# ECC_AGGR0_ECC_AGGR register map
Vendor: Texas Instruments
Peripheral module from a debugger description file (folder am65x).
Registers are 32-bit, access not given, reset 0x0 unless marked. A register's access mark holds for its fields unless they carry their own. Offsets are as the file gives them; lines under a group give offsets from that group; [hi:lo] are bit positions; {n}, {i} and the like mark numbered series; 'fields as' and 'values as' point back to an identical list; <NAME> marks a mode.

## ECC_AGGR0_ECC_AGGR (part 1 of 2)
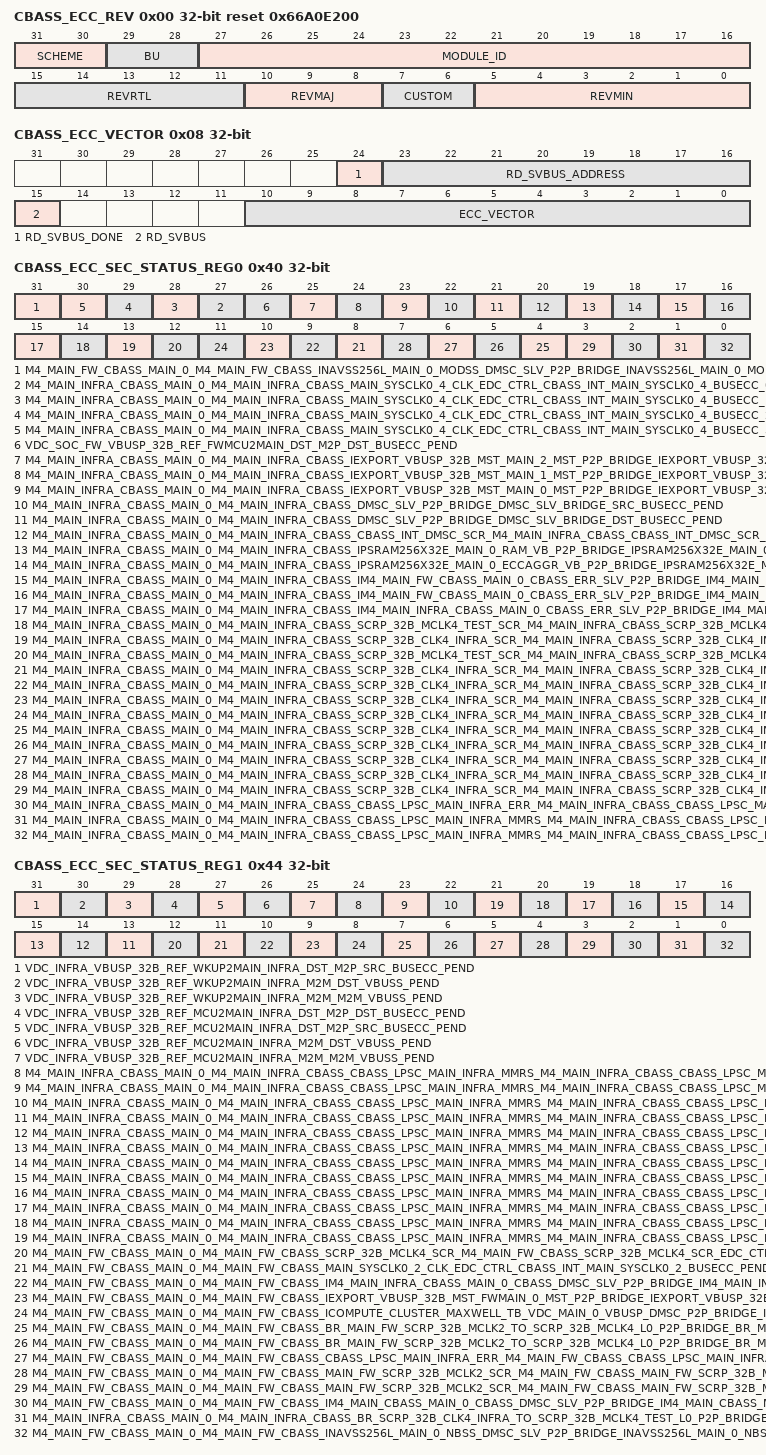
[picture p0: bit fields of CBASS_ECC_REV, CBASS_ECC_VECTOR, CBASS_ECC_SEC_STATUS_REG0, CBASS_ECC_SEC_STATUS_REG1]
0x00 CBASS_ECC_REV ro reset 0x66A0E200 — Return to the . Revision parameters
  [31:30] SCHEME
  [29:28] BU
  [27:16] MODULE_ID
  [15:11] REVRTL — RTL version
  [10:8] REVMAJ — Major version
  [7:6] CUSTOM — Custom version
  [5:0] REVMIN — Minor version
0x08 CBASS_ECC_VECTOR — Return to the . ECC Vector Register
  [24] RD_SVBUS_DONE — Status to indicate if read on serial VBUS is complete, write of any value will clear this bit. (access RW1C)
  [23:16] RD_SVBUS_ADDRESS rw — Read address
  [15] RD_SVBUS — Write 1 to trigger a read on the serial VBUS (access RW1S)
  [10:0] ECC_VECTOR rw — Value written to select the corresponding ECC RAM for control or status
0x0C CBASS_ECC_STAT ro reset 0x44 — Return to the . Misc Status
  [10:0] NUM_RAMS — Indicates the number of RAMS serviced by the ECC aggregator
0x3C CBASS_ECC_SEC_EOI_REG — Return to the . EOI Register
  [0] EOI_WR — EOI Register (access RW1S)
0x40 CBASS_ECC_SEC_STATUS_REG0 — Return to the . Interrupt Status Register 0
  [31] M4_MAIN_FW_CBASS_MAIN_0_M4_MAIN_FW_CBASS_INAVSS256L_MAIN_0_MODSS_DMSC_SLV_P2P_BRIDGE_INAVSS256L_MAIN_0_MODSS_DMSC_SLV_BRIDGE_BUSECC_PEND — Interrupt Pending Status for m4_main_fw_cbass_main_0_m4_main_fw_cbass_Inavss256l_main_0_modss_dmsc_slv_p2p_bridge_Inavss256l_main_0_modss_dmsc_slv_bridge_busecc__pend (access RW1S)
  [n+27] M4_MAIN_INFRA_CBASS_MAIN_0_M4_MAIN_INFRA_CBASS_MAIN_SYSCLK0_4_CLK_EDC_CTRL_CBASS_INT_MAIN_SYSCLK0_4_BUSECC_{n}_PEND (n=0..3) — Interrupt Pending Status for m4_main_infra_cbass_main_0_m4_main_infra_cbass_main_sysclk0_4_clk_edc_ctrl_cbass_int_main_sysclk0_4_busecc_{n}__pend (access RW1S)
  [26] VDC_SOC_FW_VBUSP_32B_REF_FWMCU2MAIN_DST_M2P_DST_BUSECC_PEND — Interrupt Pending Status for vdc_soc_fw_vbusp_32b_ref_fwmcu2main_dst_m2p_dst_busecc__pend (access RW1S)
  [25] M4_MAIN_INFRA_CBASS_MAIN_0_M4_MAIN_INFRA_CBASS_IEXPORT_VBUSP_32B_MST_MAIN_2_MST_P2P_BRIDGE_IEXPORT_VBUSP_32B_MST_MAIN_2_MST_BRIDGE_BUSECC_PEND — Interrupt Pending Status for m4_main_infra_cbass_main_0_m4_main_infra_cbass_Iexport_vbusp_32b_mst_main_2_mst_p2p_bridge_Iexport_vbusp_32b_mst_main_2_mst_bridge_busecc__pend (access RW1S)
  [24] M4_MAIN_INFRA_CBASS_MAIN_0_M4_MAIN_INFRA_CBASS_IEXPORT_VBUSP_32B_MST_MAIN_1_MST_P2P_BRIDGE_IEXPORT_VBUSP_32B_MST_MAIN_1_MST_BRIDGE_BUSECC_PEND — Interrupt Pending Status for m4_main_infra_cbass_main_0_m4_main_infra_cbass_Iexport_vbusp_32b_mst_main_1_mst_p2p_bridge_Iexport_vbusp_32b_mst_main_1_mst_bridge_busecc__pend (access RW1S)
  [23] M4_MAIN_INFRA_CBASS_MAIN_0_M4_MAIN_INFRA_CBASS_IEXPORT_VBUSP_32B_MST_MAIN_0_MST_P2P_BRIDGE_IEXPORT_VBUSP_32B_MST_MAIN_0_MST_BRIDGE_BUSECC_PEND — Interrupt Pending Status for m4_main_infra_cbass_main_0_m4_main_infra_cbass_Iexport_vbusp_32b_mst_main_0_mst_p2p_bridge_Iexport_vbusp_32b_mst_main_0_mst_bridge_busecc__pend (access RW1S)
  [22] M4_MAIN_INFRA_CBASS_MAIN_0_M4_MAIN_INFRA_CBASS_DMSC_SLV_P2P_BRIDGE_DMSC_SLV_BRIDGE_SRC_BUSECC_PEND — Interrupt Pending Status for m4_main_infra_cbass_main_0_m4_main_infra_cbass_dmsc_slv_p2p_bridge_dmsc_slv_bridge_src_busecc__pend (access RW1S)
  [21] M4_MAIN_INFRA_CBASS_MAIN_0_M4_MAIN_INFRA_CBASS_DMSC_SLV_P2P_BRIDGE_DMSC_SLV_BRIDGE_DST_BUSECC_PEND — Interrupt Pending Status for m4_main_infra_cbass_main_0_m4_main_infra_cbass_dmsc_slv_p2p_bridge_dmsc_slv_bridge_dst_busecc__pend (access RW1S)
  [20] M4_MAIN_INFRA_CBASS_MAIN_0_M4_MAIN_INFRA_CBASS_CBASS_INT_DMSC_SCR_M4_MAIN_INFRA_CBASS_CBASS_INT_DMSC_SCR_EDC_CTRL_BUSECC_PEND — Interrupt Pending Status for m4_main_infra_cbass_main_0_m4_main_infra_cbass_cbass_int_dmsc_scr_m4_main_infra_cbass_cbass_int_dmsc_scr_edc_ctrl_busecc__pend (access RW1S)
  [19] M4_MAIN_INFRA_CBASS_MAIN_0_M4_MAIN_INFRA_CBASS_IPSRAM256X32E_MAIN_0_RAM_VB_P2P_BRIDGE_IPSRAM256X32E_MAIN_0_RAM_VB_BRIDGE_BUSECC_PEND — Interrupt Pending Status for m4_main_infra_cbass_main_0_m4_main_infra_cbass_Ipsram256x32e_main_0_ram_vb_p2p_bridge_Ipsram256x32e_main_0_ram_vb_bridge_busecc__pend (access RW1S)
  [18] M4_MAIN_INFRA_CBASS_MAIN_0_M4_MAIN_INFRA_CBASS_IPSRAM256X32E_MAIN_0_ECCAGGR_VB_P2P_BRIDGE_IPSRAM256X32E_MAIN_0_ECCAGGR_VB_BRIDGE_BUSECC_PEND — Interrupt Pending Status for m4_main_infra_cbass_main_0_m4_main_infra_cbass_Ipsram256x32e_main_0_eccaggr_vb_p2p_bridge_Ipsram256x32e_main_0_eccaggr_vb_bridge_busecc__pend (access RW1S)
  [17] M4_MAIN_INFRA_CBASS_MAIN_0_M4_MAIN_INFRA_CBASS_IM4_MAIN_FW_CBASS_MAIN_0_CBASS_ERR_SLV_P2P_BRIDGE_IM4_MAIN_FW_CBASS_MAIN_0_CBASS_ERR_SLV_BRIDGE_SRC_BUSECC_PEND — Interrupt Pending Status for m4_main_infra_cbass_main_0_m4_main_infra_cbass_Im4_main_fw_cbass_main_0_cbass_err_slv_p2p_bridge_Im4_main_fw_cbass_main_0_cbass_err_slv_bridge_src_busecc__pend (access RW1S)
  [16] M4_MAIN_INFRA_CBASS_MAIN_0_M4_MAIN_INFRA_CBASS_IM4_MAIN_FW_CBASS_MAIN_0_CBASS_ERR_SLV_P2P_BRIDGE_IM4_MAIN_FW_CBASS_MAIN_0_CBASS_ERR_SLV_BRIDGE_DST_BUSECC_PEND — Interrupt Pending Status for m4_main_infra_cbass_main_0_m4_main_infra_cbass_Im4_main_fw_cbass_main_0_cbass_err_slv_p2p_bridge_Im4_main_fw_cbass_main_0_cbass_err_slv_bridge_dst_busecc__pend (access RW1S)
  [15] M4_MAIN_INFRA_CBASS_MAIN_0_M4_MAIN_INFRA_CBASS_IM4_MAIN_INFRA_CBASS_MAIN_0_CBASS_ERR_SLV_P2P_BRIDGE_IM4_MAIN_INFRA_CBASS_MAIN_0_CBASS_ERR_SLV_BRIDGE_BUSECC_PEND — Interrupt Pending Status for m4_main_infra_cbass_main_0_m4_main_infra_cbass_Im4_main_infra_cbass_main_0_cbass_err_slv_p2p_bridge_Im4_main_infra_cbass_main_0_cbass_err_slv_bridge_busecc__pend (access RW1S)
  [14] M4_MAIN_INFRA_CBASS_MAIN_0_M4_MAIN_INFRA_CBASS_SCRP_32B_MCLK4_TEST_SCR_M4_MAIN_INFRA_CBASS_SCRP_32B_MCLK4_TEST_SCR_EDC_CTRL_BUSECC_1_PEND — Interrupt Pending Status for m4_main_infra_cbass_main_0_m4_main_infra_cbass_SCRP_32b_MCLK4_test_scr_m4_main_infra_cbass_SCRP_32b_MCLK4_test_scr_edc_ctrl_busecc_1__pend (access RW1S)
  [13] M4_MAIN_INFRA_CBASS_MAIN_0_M4_MAIN_INFRA_CBASS_SCRP_32B_CLK4_INFRA_SCR_M4_MAIN_INFRA_CBASS_SCRP_32B_CLK4_INFRA_SCR_EDC_CTRL_BUSECC_9_PEND — Interrupt Pending Status for m4_main_infra_cbass_main_0_m4_main_infra_cbass_SCRP_32b_CLK4_infra_scr_m4_main_infra_cbass_SCRP_32b_CLK4_infra_scr_edc_ctrl_busecc_9__pend (access RW1S)
  [12] M4_MAIN_INFRA_CBASS_MAIN_0_M4_MAIN_INFRA_CBASS_SCRP_32B_MCLK4_TEST_SCR_M4_MAIN_INFRA_CBASS_SCRP_32B_MCLK4_TEST_SCR_EDC_CTRL_BUSECC_0_PEND — Interrupt Pending Status for m4_main_infra_cbass_main_0_m4_main_infra_cbass_SCRP_32b_MCLK4_test_scr_m4_main_infra_cbass_SCRP_32b_MCLK4_test_scr_edc_ctrl_busecc_0__pend (access RW1S)
  [n+3] M4_MAIN_INFRA_CBASS_MAIN_0_M4_MAIN_INFRA_CBASS_SCRP_32B_CLK4_INFRA_SCR_M4_MAIN_INFRA_CBASS_SCRP_32B_CLK4_INFRA_SCR_EDC_CTRL_BUSECC_{n}_PEND (n=5..8) — Interrupt Pending Status for m4_main_infra_cbass_main_0_m4_main_infra_cbass_SCRP_32b_CLK4_infra_scr_m4_main_infra_cbass_SCRP_32b_CLK4_infra_scr_edc_ctrl_busecc_{n}__pend (access RW1S)
  [n+4] M4_MAIN_INFRA_CBASS_MAIN_0_M4_MAIN_INFRA_CBASS_SCRP_32B_CLK4_INFRA_SCR_M4_MAIN_INFRA_CBASS_SCRP_32B_CLK4_INFRA_SCR_EDC_CTRL_BUSECC_{n}_PEND (n=0..3) — Interrupt Pending Status for m4_main_infra_cbass_main_0_m4_main_infra_cbass_SCRP_32b_CLK4_infra_scr_m4_main_infra_cbass_SCRP_32b_CLK4_infra_scr_edc_ctrl_busecc_{n}__pend (access RW1S)
  [3] M4_MAIN_INFRA_CBASS_MAIN_0_M4_MAIN_INFRA_CBASS_SCRP_32B_CLK4_INFRA_SCR_M4_MAIN_INFRA_CBASS_SCRP_32B_CLK4_INFRA_SCR_EDC_CTRL_BUSECC_4_PEND — Interrupt Pending Status for m4_main_infra_cbass_main_0_m4_main_infra_cbass_SCRP_32b_CLK4_infra_scr_m4_main_infra_cbass_SCRP_32b_CLK4_infra_scr_edc_ctrl_busecc_4__pend (access RW1S)
  [2] M4_MAIN_INFRA_CBASS_MAIN_0_M4_MAIN_INFRA_CBASS_CBASS_LPSC_MAIN_INFRA_ERR_M4_MAIN_INFRA_CBASS_CBASS_LPSC_MAIN_INFRA_ERR_EDC_CTRL_BUSECC_PEND — Interrupt Pending Status for m4_main_infra_cbass_main_0_m4_main_infra_cbass_cbass_LPSC_main_infra_err_m4_main_infra_cbass_cbass_LPSC_main_infra_err_edc_ctrl_busecc__pend (access RW1S)
  [1] M4_MAIN_INFRA_CBASS_MAIN_0_M4_MAIN_INFRA_CBASS_CBASS_LPSC_MAIN_INFRA_MMRS_M4_MAIN_INFRA_CBASS_CBASS_LPSC_MAIN_INFRA_MMRS_EDC_CTRL_BUSECC_10_PEND — Interrupt Pending Status for m4_main_infra_cbass_main_0_m4_main_infra_cbass_cbass_LPSC_main_infra_mmrs_m4_main_infra_cbass_cbass_LPSC_main_infra_mmrs_edc_ctrl_busecc_10__pend (access RW1S)
  [0] M4_MAIN_INFRA_CBASS_MAIN_0_M4_MAIN_INFRA_CBASS_CBASS_LPSC_MAIN_INFRA_MMRS_M4_MAIN_INFRA_CBASS_CBASS_LPSC_MAIN_INFRA_MMRS_EDC_CTRL_BUSECC_0_PEND — Interrupt Pending Status for m4_main_infra_cbass_main_0_m4_main_infra_cbass_cbass_LPSC_main_infra_mmrs_m4_main_infra_cbass_cbass_LPSC_main_infra_mmrs_edc_ctrl_busecc_0__pend (access RW1S)
0x44 CBASS_ECC_SEC_STATUS_REG1 — Return to the . Interrupt Status Register 1
  [31] VDC_INFRA_VBUSP_32B_REF_WKUP2MAIN_INFRA_DST_M2P_SRC_BUSECC_PEND — Interrupt Pending Status for vdc_infra_vbusp_32b_ref_wkup2main_infra_dst_m2p_src_busecc__pend (access RW1S)
  [30] VDC_INFRA_VBUSP_32B_REF_WKUP2MAIN_INFRA_M2M_DST_VBUSS_PEND — Interrupt Pending Status for vdc_infra_vbusp_32b_ref_wkup2main_infra_m2m_dst_vbuss__pend (access RW1S)
  [29] VDC_INFRA_VBUSP_32B_REF_WKUP2MAIN_INFRA_M2M_M2M_VBUSS_PEND — Interrupt Pending Status for vdc_infra_vbusp_32b_ref_wkup2main_infra_m2m_m2m_vbuss__pend (access RW1S)
  [28] VDC_INFRA_VBUSP_32B_REF_MCU2MAIN_INFRA_DST_M2P_DST_BUSECC_PEND — Interrupt Pending Status for vdc_infra_vbusp_32b_ref_mcu2main_infra_dst_m2p_dst_busecc__pend (access RW1S)
  [27] VDC_INFRA_VBUSP_32B_REF_MCU2MAIN_INFRA_DST_M2P_SRC_BUSECC_PEND — Interrupt Pending Status for vdc_infra_vbusp_32b_ref_mcu2main_infra_dst_m2p_src_busecc__pend (access RW1S)
  [26] VDC_INFRA_VBUSP_32B_REF_MCU2MAIN_INFRA_M2M_DST_VBUSS_PEND — Interrupt Pending Status for vdc_infra_vbusp_32b_ref_mcu2main_infra_m2m_dst_vbuss__pend (access RW1S)
  [25] VDC_INFRA_VBUSP_32B_REF_MCU2MAIN_INFRA_M2M_M2M_VBUSS_PEND — Interrupt Pending Status for vdc_infra_vbusp_32b_ref_mcu2main_infra_m2m_m2m_vbuss__pend (access RW1S)
  [24] M4_MAIN_INFRA_CBASS_MAIN_0_M4_MAIN_INFRA_CBASS_CBASS_LPSC_MAIN_INFRA_MMRS_M4_MAIN_INFRA_CBASS_CBASS_LPSC_MAIN_INFRA_MMRS_EDC_CTRL_BUSECC_13_PEND — Interrupt Pending Status for m4_main_infra_cbass_main_0_m4_main_infra_cbass_cbass_LPSC_main_infra_mmrs_m4_main_infra_cbass_cbass_LPSC_main_infra_mmrs_edc_ctrl_busecc_13__pend (access RW1S)
  [23] M4_MAIN_INFRA_CBASS_MAIN_0_M4_MAIN_INFRA_CBASS_CBASS_LPSC_MAIN_INFRA_MMRS_M4_MAIN_INFRA_CBASS_CBASS_LPSC_MAIN_INFRA_MMRS_EDC_CTRL_BUSECC_12_PEND — Interrupt Pending Status for m4_main_infra_cbass_main_0_m4_main_infra_cbass_cbass_LPSC_main_infra_mmrs_m4_main_infra_cbass_cbass_LPSC_main_infra_mmrs_edc_ctrl_busecc_12__pend (access RW1S)
  [22] M4_MAIN_INFRA_CBASS_MAIN_0_M4_MAIN_INFRA_CBASS_CBASS_LPSC_MAIN_INFRA_MMRS_M4_MAIN_INFRA_CBASS_CBASS_LPSC_MAIN_INFRA_MMRS_EDC_CTRL_BUSECC_11_PEND — Interrupt Pending Status for m4_main_infra_cbass_main_0_m4_main_infra_cbass_cbass_LPSC_main_infra_mmrs_m4_main_infra_cbass_cbass_LPSC_main_infra_mmrs_edc_ctrl_busecc_11__pend (access RW1S)
  [n+12] M4_MAIN_INFRA_CBASS_MAIN_0_M4_MAIN_INFRA_CBASS_CBASS_LPSC_MAIN_INFRA_MMRS_M4_MAIN_INFRA_CBASS_CBASS_LPSC_MAIN_INFRA_MMRS_EDC_CTRL_BUSECC_{n}_PEND (n=1..9) — Interrupt Pending Status for m4_main_infra_cbass_main_0_m4_main_infra_cbass_cbass_LPSC_main_infra_mmrs_m4_main_infra_cbass_cbass_LPSC_main_infra_mmrs_edc_ctrl_busecc_{n}__pend (access RW1S)
  [12] M4_MAIN_FW_CBASS_MAIN_0_M4_MAIN_FW_CBASS_SCRP_32B_MCLK4_SCR_M4_MAIN_FW_CBASS_SCRP_32B_MCLK4_SCR_EDC_CTRL_BUSECC_PEND — Interrupt Pending Status for m4_main_fw_cbass_main_0_m4_main_fw_cbass_SCRP_32b_MCLK4_scr_m4_main_fw_cbass_SCRP_32b_MCLK4_scr_edc_ctrl_busecc__pend (access RW1S)
  [11] M4_MAIN_FW_CBASS_MAIN_0_M4_MAIN_FW_CBASS_MAIN_SYSCLK0_2_CLK_EDC_CTRL_CBASS_INT_MAIN_SYSCLK0_2_BUSECC_PEND — Interrupt Pending Status for m4_main_fw_cbass_main_0_m4_main_fw_cbass_main_sysclk0_2_clk_edc_ctrl_cbass_int_main_sysclk0_2_busecc__pend (access RW1S)
  [10] M4_MAIN_FW_CBASS_MAIN_0_M4_MAIN_FW_CBASS_IM4_MAIN_INFRA_CBASS_MAIN_0_CBASS_DMSC_SLV_P2P_BRIDGE_IM4_MAIN_INFRA_CBASS_MAIN_0_CBASS_DMSC_SLV_BRIDGE_BUSECC_PEND — Interrupt Pending Status for m4_main_fw_cbass_main_0_m4_main_fw_cbass_Im4_main_infra_cbass_main_0_cbass_dmsc_slv_p2p_bridge_Im4_main_infra_cbass_main_0_cbass_dmsc_slv_bridge_busecc__pend (access RW1S)
  [9] M4_MAIN_FW_CBASS_MAIN_0_M4_MAIN_FW_CBASS_IEXPORT_VBUSP_32B_MST_FWMAIN_0_MST_P2P_BRIDGE_IEXPORT_VBUSP_32B_MST_FWMAIN_0_MST_BRIDGE_BUSECC_PEND — Interrupt Pending Status for m4_main_fw_cbass_main_0_m4_main_fw_cbass_Iexport_vbusp_32b_mst_fwmain_0_mst_p2p_bridge_Iexport_vbusp_32b_mst_fwmain_0_mst_bridge_busecc__pend (access RW1S)
  [8] M4_MAIN_FW_CBASS_MAIN_0_M4_MAIN_FW_CBASS_ICOMPUTE_CLUSTER_MAXWELL_TB_VDC_MAIN_0_VBUSP_DMSC_P2P_BRIDGE_ICOMPUTE_CLUSTER_MAXWELL_TB_VDC_MAIN_0_VBUSP_DMSC_BRIDGE_BUSECC_PEND — Interrupt Pending Status for m4_main_fw_cbass_main_0_m4_main_fw_cbass_Icompute_cluster_maxwell_tb_vdc_main_0_vbusp_dmsc_p2p_bridge_Icompute_cluster_maxwell_tb_vdc_main_0_vbusp_dmsc_bridge_busecc__pend (access RW1S)
  [7] M4_MAIN_FW_CBASS_MAIN_0_M4_MAIN_FW_CBASS_BR_MAIN_FW_SCRP_32B_MCLK2_TO_SCRP_32B_MCLK4_L0_P2P_BRIDGE_BR_MAIN_FW_SCRP_32B_MCLK2_TO_SCRP_32B_MCLK4_L0_BRIDGE_SRC_BUSECC_PEND — Interrupt Pending Status for m4_main_fw_cbass_main_0_m4_main_fw_cbass_br_main_FW_SCRP_32b_MCLK2_to_SCRP_32b_MCLK4_l0_p2p_bridge_br_main_FW_SCRP_32b_MCLK2_to_SCRP_32b_MCLK4_l0_bridge_src_busecc__pend (access RW1S)
  [6] M4_MAIN_FW_CBASS_MAIN_0_M4_MAIN_FW_CBASS_BR_MAIN_FW_SCRP_32B_MCLK2_TO_SCRP_32B_MCLK4_L0_P2P_BRIDGE_BR_MAIN_FW_SCRP_32B_MCLK2_TO_SCRP_32B_MCLK4_L0_BRIDGE_DST_BUSECC_PEND — Interrupt Pending Status for m4_main_fw_cbass_main_0_m4_main_fw_cbass_br_main_FW_SCRP_32b_MCLK2_to_SCRP_32b_MCLK4_l0_p2p_bridge_br_main_FW_SCRP_32b_MCLK2_to_SCRP_32b_MCLK4_l0_bridge_dst_busecc__pend (access RW1S)
  [5] M4_MAIN_FW_CBASS_MAIN_0_M4_MAIN_FW_CBASS_CBASS_LPSC_MAIN_INFRA_ERR_M4_MAIN_FW_CBASS_CBASS_LPSC_MAIN_INFRA_ERR_EDC_CTRL_BUSECC_PEND — Interrupt Pending Status for m4_main_fw_cbass_main_0_m4_main_fw_cbass_cbass_LPSC_main_infra_err_m4_main_fw_cbass_cbass_LPSC_main_infra_err_edc_ctrl_busecc__pend (access RW1S)
  [4] M4_MAIN_FW_CBASS_MAIN_0_M4_MAIN_FW_CBASS_MAIN_FW_SCRP_32B_MCLK2_SCR_M4_MAIN_FW_CBASS_MAIN_FW_SCRP_32B_MCLK2_SCR_EDC_CTRL_BUSECC_1_PEND — Interrupt Pending Status for m4_main_fw_cbass_main_0_m4_main_fw_cbass_main_FW_SCRP_32b_MCLK2_scr_m4_main_fw_cbass_main_FW_SCRP_32b_MCLK2_scr_edc_ctrl_busecc_1__pend (access RW1S)
  [3] M4_MAIN_FW_CBASS_MAIN_0_M4_MAIN_FW_CBASS_MAIN_FW_SCRP_32B_MCLK2_SCR_M4_MAIN_FW_CBASS_MAIN_FW_SCRP_32B_MCLK2_SCR_EDC_CTRL_BUSECC_0_PEND — Interrupt Pending Status for m4_main_fw_cbass_main_0_m4_main_fw_cbass_main_FW_SCRP_32b_MCLK2_scr_m4_main_fw_cbass_main_FW_SCRP_32b_MCLK2_scr_edc_ctrl_busecc_0__pend (access RW1S)
  [2] M4_MAIN_FW_CBASS_MAIN_0_M4_MAIN_FW_CBASS_IM4_MAIN_CBASS_MAIN_0_CBASS_DMSC_SLV_P2P_BRIDGE_IM4_MAIN_CBASS_MAIN_0_CBASS_DMSC_SLV_BRIDGE_BUSECC_PEND — Interrupt Pending Status for m4_main_fw_cbass_main_0_m4_main_fw_cbass_Im4_main_cbass_main_0_cbass_dmsc_slv_p2p_bridge_Im4_main_cbass_main_0_cbass_dmsc_slv_bridge_busecc__pend (access RW1S)
  [1] M4_MAIN_INFRA_CBASS_MAIN_0_M4_MAIN_INFRA_CBASS_BR_SCRP_32B_CLK4_INFRA_TO_SCRP_32B_MCLK4_TEST_L0_P2P_BRIDGE_BR_SCRP_32B_CLK4_INFRA_TO_SCRP_32B_MCLK4_TEST_L0_BRIDGE_BUSECC_PEND — Interrupt Pending Status for m4_main_infra_cbass_main_0_m4_main_infra_cbass_br_SCRP_32b_CLK4_infra_to_SCRP_32b_MCLK4_test_l0_p2p_bridge_br_SCRP_32b_CLK4_infra_to_SCRP_32b_MCLK4_test_l0_bridge_busecc__pend (access RW1S)
  [0] M4_MAIN_FW_CBASS_MAIN_0_M4_MAIN_FW_CBASS_INAVSS256L_MAIN_0_NBSS_DMSC_SLV_P2P_BRIDGE_INAVSS256L_MAIN_0_NBSS_DMSC_SLV_BRIDGE_BUSECC_PEND — Interrupt Pending Status for m4_main_fw_cbass_main_0_m4_main_fw_cbass_Inavss256l_main_0_nbss_dmsc_slv_p2p_bridge_Inavss256l_main_0_nbss_dmsc_slv_bridge_busecc__pend (access RW1S)
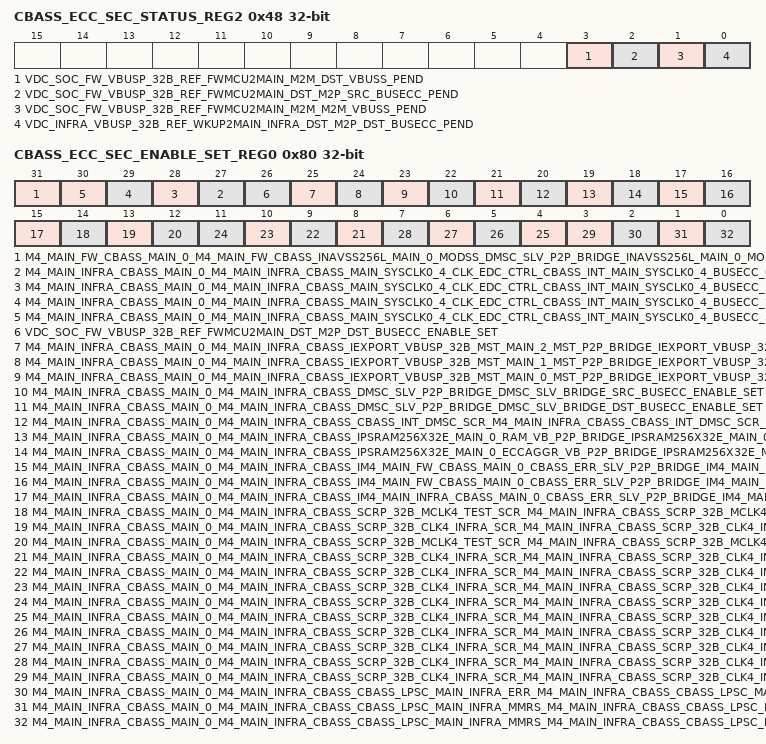
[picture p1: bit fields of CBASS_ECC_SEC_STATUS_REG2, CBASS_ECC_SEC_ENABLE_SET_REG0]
0x48 CBASS_ECC_SEC_STATUS_REG2 — Return to the . Interrupt Status Register 2
  [3] VDC_SOC_FW_VBUSP_32B_REF_FWMCU2MAIN_M2M_DST_VBUSS_PEND — Interrupt Pending Status for vdc_soc_fw_vbusp_32b_ref_fwmcu2main_m2m_dst_vbuss__pend (access RW1S)
  [2] VDC_SOC_FW_VBUSP_32B_REF_FWMCU2MAIN_DST_M2P_SRC_BUSECC_PEND — Interrupt Pending Status for vdc_soc_fw_vbusp_32b_ref_fwmcu2main_dst_m2p_src_busecc__pend (access RW1S)
  [1] VDC_SOC_FW_VBUSP_32B_REF_FWMCU2MAIN_M2M_M2M_VBUSS_PEND — Interrupt Pending Status for vdc_soc_fw_vbusp_32b_ref_fwmcu2main_m2m_m2m_vbuss__pend (access RW1S)
  [0] VDC_INFRA_VBUSP_32B_REF_WKUP2MAIN_INFRA_DST_M2P_DST_BUSECC_PEND — Interrupt Pending Status for vdc_infra_vbusp_32b_ref_wkup2main_infra_dst_m2p_dst_busecc__pend (access RW1S)
0x80 CBASS_ECC_SEC_ENABLE_SET_REG0 — Return to the . Interrupt Enable Set Register 0
  [31] M4_MAIN_FW_CBASS_MAIN_0_M4_MAIN_FW_CBASS_INAVSS256L_MAIN_0_MODSS_DMSC_SLV_P2P_BRIDGE_INAVSS256L_MAIN_0_MODSS_DMSC_SLV_BRIDGE_BUSECC_ENABLE_SET — Interrupt Enable Set Register for m4_main_fw_cbass_main_0_m4_main_fw_cbass_Inavss256l_main_0_modss_dmsc_slv_p2p_bridge_Inavss256l_main_0_modss_dmsc_slv_bridge_busecc__pend (access RW1S)
  [n+27] M4_MAIN_INFRA_CBASS_MAIN_0_M4_MAIN_INFRA_CBASS_MAIN_SYSCLK0_4_CLK_EDC_CTRL_CBASS_INT_MAIN_SYSCLK0_4_BUSECC_{n}_ENABLE_SET (n=0..3) — Interrupt Enable Set Register for m4_main_infra_cbass_main_0_m4_main_infra_cbass_main_sysclk0_4_clk_edc_ctrl_cbass_int_main_sysclk0_4_busecc_{n}__pend (access RW1S)
  [26] VDC_SOC_FW_VBUSP_32B_REF_FWMCU2MAIN_DST_M2P_DST_BUSECC_ENABLE_SET — Interrupt Enable Set Register for vdc_soc_fw_vbusp_32b_ref_fwmcu2main_dst_m2p_dst_busecc__pend (access RW1S)
  [25] M4_MAIN_INFRA_CBASS_MAIN_0_M4_MAIN_INFRA_CBASS_IEXPORT_VBUSP_32B_MST_MAIN_2_MST_P2P_BRIDGE_IEXPORT_VBUSP_32B_MST_MAIN_2_MST_BRIDGE_BUSECC_ENABLE_SET — Interrupt Enable Set Register for m4_main_infra_cbass_main_0_m4_main_infra_cbass_Iexport_vbusp_32b_mst_main_2_mst_p2p_bridge_Iexport_vbusp_32b_mst_main_2_mst_bridge_busecc__pend (access RW1S)
  [24] M4_MAIN_INFRA_CBASS_MAIN_0_M4_MAIN_INFRA_CBASS_IEXPORT_VBUSP_32B_MST_MAIN_1_MST_P2P_BRIDGE_IEXPORT_VBUSP_32B_MST_MAIN_1_MST_BRIDGE_BUSECC_ENABLE_SET — Interrupt Enable Set Register for m4_main_infra_cbass_main_0_m4_main_infra_cbass_Iexport_vbusp_32b_mst_main_1_mst_p2p_bridge_Iexport_vbusp_32b_mst_main_1_mst_bridge_busecc__pend (access RW1S)
  [23] M4_MAIN_INFRA_CBASS_MAIN_0_M4_MAIN_INFRA_CBASS_IEXPORT_VBUSP_32B_MST_MAIN_0_MST_P2P_BRIDGE_IEXPORT_VBUSP_32B_MST_MAIN_0_MST_BRIDGE_BUSECC_ENABLE_SET — Interrupt Enable Set Register for m4_main_infra_cbass_main_0_m4_main_infra_cbass_Iexport_vbusp_32b_mst_main_0_mst_p2p_bridge_Iexport_vbusp_32b_mst_main_0_mst_bridge_busecc__pend (access RW1S)
  [22] M4_MAIN_INFRA_CBASS_MAIN_0_M4_MAIN_INFRA_CBASS_DMSC_SLV_P2P_BRIDGE_DMSC_SLV_BRIDGE_SRC_BUSECC_ENABLE_SET — Interrupt Enable Set Register for m4_main_infra_cbass_main_0_m4_main_infra_cbass_dmsc_slv_p2p_bridge_dmsc_slv_bridge_src_busecc__pend (access RW1S)
  [21] M4_MAIN_INFRA_CBASS_MAIN_0_M4_MAIN_INFRA_CBASS_DMSC_SLV_P2P_BRIDGE_DMSC_SLV_BRIDGE_DST_BUSECC_ENABLE_SET — Interrupt Enable Set Register for m4_main_infra_cbass_main_0_m4_main_infra_cbass_dmsc_slv_p2p_bridge_dmsc_slv_bridge_dst_busecc__pend (access RW1S)
  [20] M4_MAIN_INFRA_CBASS_MAIN_0_M4_MAIN_INFRA_CBASS_CBASS_INT_DMSC_SCR_M4_MAIN_INFRA_CBASS_CBASS_INT_DMSC_SCR_EDC_CTRL_BUSECC_ENABLE_SET — Interrupt Enable Set Register for m4_main_infra_cbass_main_0_m4_main_infra_cbass_cbass_int_dmsc_scr_m4_main_infra_cbass_cbass_int_dmsc_scr_edc_ctrl_busecc__pend (access RW1S)
  [19] M4_MAIN_INFRA_CBASS_MAIN_0_M4_MAIN_INFRA_CBASS_IPSRAM256X32E_MAIN_0_RAM_VB_P2P_BRIDGE_IPSRAM256X32E_MAIN_0_RAM_VB_BRIDGE_BUSECC_ENABLE_SET — Interrupt Enable Set Register for m4_main_infra_cbass_main_0_m4_main_infra_cbass_Ipsram256x32e_main_0_ram_vb_p2p_bridge_Ipsram256x32e_main_0_ram_vb_bridge_busecc__pend (access RW1S)
  [18] M4_MAIN_INFRA_CBASS_MAIN_0_M4_MAIN_INFRA_CBASS_IPSRAM256X32E_MAIN_0_ECCAGGR_VB_P2P_BRIDGE_IPSRAM256X32E_MAIN_0_ECCAGGR_VB_BRIDGE_BUSECC_ENABLE_SET — Interrupt Enable Set Register for m4_main_infra_cbass_main_0_m4_main_infra_cbass_Ipsram256x32e_main_0_eccaggr_vb_p2p_bridge_Ipsram256x32e_main_0_eccaggr_vb_bridge_busecc__pend (access RW1S)
  [17] M4_MAIN_INFRA_CBASS_MAIN_0_M4_MAIN_INFRA_CBASS_IM4_MAIN_FW_CBASS_MAIN_0_CBASS_ERR_SLV_P2P_BRIDGE_IM4_MAIN_FW_CBASS_MAIN_0_CBASS_ERR_SLV_BRIDGE_SRC_BUSECC_ENABLE_SET — Interrupt Enable Set Register for m4_main_infra_cbass_main_0_m4_main_infra_cbass_Im4_main_fw_cbass_main_0_cbass_err_slv_p2p_bridge_Im4_main_fw_cbass_main_0_cbass_err_slv_bridge_src_busecc__pend (access RW1S)
  [16] M4_MAIN_INFRA_CBASS_MAIN_0_M4_MAIN_INFRA_CBASS_IM4_MAIN_FW_CBASS_MAIN_0_CBASS_ERR_SLV_P2P_BRIDGE_IM4_MAIN_FW_CBASS_MAIN_0_CBASS_ERR_SLV_BRIDGE_DST_BUSECC_ENABLE_SET — Interrupt Enable Set Register for m4_main_infra_cbass_main_0_m4_main_infra_cbass_Im4_main_fw_cbass_main_0_cbass_err_slv_p2p_bridge_Im4_main_fw_cbass_main_0_cbass_err_slv_bridge_dst_busecc__pend (access RW1S)
  [15] M4_MAIN_INFRA_CBASS_MAIN_0_M4_MAIN_INFRA_CBASS_IM4_MAIN_INFRA_CBASS_MAIN_0_CBASS_ERR_SLV_P2P_BRIDGE_IM4_MAIN_INFRA_CBASS_MAIN_0_CBASS_ERR_SLV_BRIDGE_BUSECC_ENABLE_SET — Interrupt Enable Set Register for m4_main_infra_cbass_main_0_m4_main_infra_cbass_Im4_main_infra_cbass_main_0_cbass_err_slv_p2p_bridge_Im4_main_infra_cbass_main_0_cbass_err_slv_bridge_busecc__pend (access RW1S)
  [14] M4_MAIN_INFRA_CBASS_MAIN_0_M4_MAIN_INFRA_CBASS_SCRP_32B_MCLK4_TEST_SCR_M4_MAIN_INFRA_CBASS_SCRP_32B_MCLK4_TEST_SCR_EDC_CTRL_BUSECC_1_ENABLE_SET — Interrupt Enable Set Register for m4_main_infra_cbass_main_0_m4_main_infra_cbass_SCRP_32b_MCLK4_test_scr_m4_main_infra_cbass_SCRP_32b_MCLK4_test_scr_edc_ctrl_busecc_1__pend (access RW1S)
  [13] M4_MAIN_INFRA_CBASS_MAIN_0_M4_MAIN_INFRA_CBASS_SCRP_32B_CLK4_INFRA_SCR_M4_MAIN_INFRA_CBASS_SCRP_32B_CLK4_INFRA_SCR_EDC_CTRL_BUSECC_9_ENABLE_SET — Interrupt Enable Set Register for m4_main_infra_cbass_main_0_m4_main_infra_cbass_SCRP_32b_CLK4_infra_scr_m4_main_infra_cbass_SCRP_32b_CLK4_infra_scr_edc_ctrl_busecc_9__pend (access RW1S)
  [12] M4_MAIN_INFRA_CBASS_MAIN_0_M4_MAIN_INFRA_CBASS_SCRP_32B_MCLK4_TEST_SCR_M4_MAIN_INFRA_CBASS_SCRP_32B_MCLK4_TEST_SCR_EDC_CTRL_BUSECC_0_ENABLE_SET — Interrupt Enable Set Register for m4_main_infra_cbass_main_0_m4_main_infra_cbass_SCRP_32b_MCLK4_test_scr_m4_main_infra_cbass_SCRP_32b_MCLK4_test_scr_edc_ctrl_busecc_0__pend (access RW1S)
  [n+3] M4_MAIN_INFRA_CBASS_MAIN_0_M4_MAIN_INFRA_CBASS_SCRP_32B_CLK4_INFRA_SCR_M4_MAIN_INFRA_CBASS_SCRP_32B_CLK4_INFRA_SCR_EDC_CTRL_BUSECC_{n}_ENABLE_SET (n=5..8) — Interrupt Enable Set Register for m4_main_infra_cbass_main_0_m4_main_infra_cbass_SCRP_32b_CLK4_infra_scr_m4_main_infra_cbass_SCRP_32b_CLK4_infra_scr_edc_ctrl_busecc_{n}__pend (access RW1S)
  [n+4] M4_MAIN_INFRA_CBASS_MAIN_0_M4_MAIN_INFRA_CBASS_SCRP_32B_CLK4_INFRA_SCR_M4_MAIN_INFRA_CBASS_SCRP_32B_CLK4_INFRA_SCR_EDC_CTRL_BUSECC_{n}_ENABLE_SET (n=0..3) — Interrupt Enable Set Register for m4_main_infra_cbass_main_0_m4_main_infra_cbass_SCRP_32b_CLK4_infra_scr_m4_main_infra_cbass_SCRP_32b_CLK4_infra_scr_edc_ctrl_busecc_{n}__pend (access RW1S)
  [3] M4_MAIN_INFRA_CBASS_MAIN_0_M4_MAIN_INFRA_CBASS_SCRP_32B_CLK4_INFRA_SCR_M4_MAIN_INFRA_CBASS_SCRP_32B_CLK4_INFRA_SCR_EDC_CTRL_BUSECC_4_ENABLE_SET — Interrupt Enable Set Register for m4_main_infra_cbass_main_0_m4_main_infra_cbass_SCRP_32b_CLK4_infra_scr_m4_main_infra_cbass_SCRP_32b_CLK4_infra_scr_edc_ctrl_busecc_4__pend (access RW1S)
  [2] M4_MAIN_INFRA_CBASS_MAIN_0_M4_MAIN_INFRA_CBASS_CBASS_LPSC_MAIN_INFRA_ERR_M4_MAIN_INFRA_CBASS_CBASS_LPSC_MAIN_INFRA_ERR_EDC_CTRL_BUSECC_ENABLE_SET — Interrupt Enable Set Register for m4_main_infra_cbass_main_0_m4_main_infra_cbass_cbass_LPSC_main_infra_err_m4_main_infra_cbass_cbass_LPSC_main_infra_err_edc_ctrl_busecc__pend (access RW1S)
  [1] M4_MAIN_INFRA_CBASS_MAIN_0_M4_MAIN_INFRA_CBASS_CBASS_LPSC_MAIN_INFRA_MMRS_M4_MAIN_INFRA_CBASS_CBASS_LPSC_MAIN_INFRA_MMRS_EDC_CTRL_BUSECC_10_ENABLE_SET — Interrupt Enable Set Register for m4_main_infra_cbass_main_0_m4_main_infra_cbass_cbass_LPSC_main_infra_mmrs_m4_main_infra_cbass_cbass_LPSC_main_infra_mmrs_edc_ctrl_busecc_10__pend (access RW1S)
  [0] M4_MAIN_INFRA_CBASS_MAIN_0_M4_MAIN_INFRA_CBASS_CBASS_LPSC_MAIN_INFRA_MMRS_M4_MAIN_INFRA_CBASS_CBASS_LPSC_MAIN_INFRA_MMRS_EDC_CTRL_BUSECC_0_ENABLE_SET — Interrupt Enable Set Register for m4_main_infra_cbass_main_0_m4_main_infra_cbass_cbass_LPSC_main_infra_mmrs_m4_main_infra_cbass_cbass_LPSC_main_infra_mmrs_edc_ctrl_busecc_0__pend (access RW1S)
